# nrf9230_sysctrl register map
Vendor: Nordic Semiconductor; Series: nRF92; File version: 1
Registers are 32-bit, read-write, reset 0x0 unless marked. A register's access mark holds for its fields unless they carry their own. Offsets are from the block's base; [hi:lo] are bit positions; {n}, {i} and the like mark numbered series; 'fields as' and 'values as' point back to an identical list; <NAME> marks a mode.

## PMICC — PMIC Controller
Base 0x5F978000
0x100 EVENTS_FPWMRDYHI — PMIC fPwmRdy went from low to high.
  [0] EVENTS_FPWMRDYHI
    0=NotGenerated (Event not generated); 1=Generated (Event generated)
0x104 EVENTS_FPWMRDYLO — PMIC fPwmRdy went from high to low.
  [0] EVENTS_FPWMRDYLO
    values as EVENTS_FPWMRDYHI.EVENTS_FPWMRDYHI
{0x108+4i} EVENTS_CURRABOVE[{i}] (i=0..8) — Description collection: Current consumption went above the threshold for power rail n. POWER_RAIL_NAME[o] index o <- ((EVENTS_CURRABOVE[n]) MOD (number of power rails))
  [0] EVENTS_CURRABOVE — Current consumption went above the threshold for power rail n. POWER_RAIL_NAME[o] index o <- ((EVENTS_CURRABOVE[n]) MOD (number of power rails))
    values as EVENTS_FPWMRDYHI.EVENTS_FPWMRDYHI
{0x12C+4i} EVENTS_CURRBELOW[{i}] (i=0..8) — Description collection: Current consumption went below the threshold for power rail n. POWER_RAIL_NAME[o] index o <- ((EVENTS_CURRBELOW[n]) MOD (number of power rails))
  [0] EVENTS_CURRBELOW — Current consumption went below the threshold for power rail n. POWER_RAIL_NAME[o] index o <- ((EVENTS_CURRBELOW[n]) MOD (number of power rails))
    values as EVENTS_FPWMRDYHI.EVENTS_FPWMRDYHI
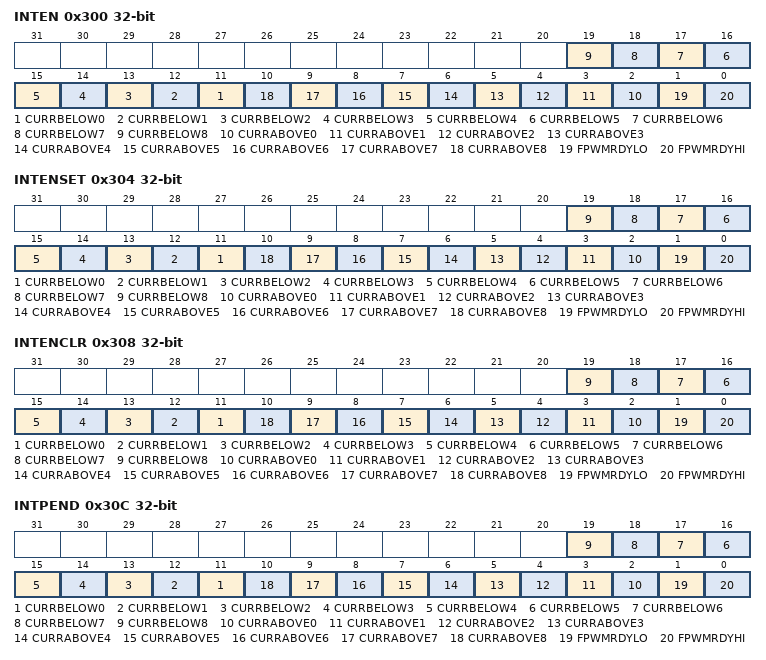
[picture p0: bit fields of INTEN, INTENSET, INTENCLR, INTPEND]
0x300 INTEN — Enable or disable interrupt
  [all] fields
    0=Disabled; 1=Enabled
  [n+11] CURRBELOW{n} (n=0..8) — Enable or disable interrupt for event CURRBELOW[{n}]
  [n+2] CURRABOVE{n} (n=0..8) — Enable or disable interrupt for event CURRABOVE[{n}]
  [1] FPWMRDYLO — Enable or disable interrupt for event FPWMRDYLO
  [0] FPWMRDYHI — Enable or disable interrupt for event FPWMRDYHI
0x304 INTENSET — Enable interrupt
  [all] fields
    on read: 0=Disabled (Read: Disabled); 1=Enabled (Read: Enabled) | on write: 1=Set (Enable)
  [n+11] CURRBELOW{n} (n=0..8) — Write '1' to enable interrupt for event CURRBELOW[{n}]
  [n+2] CURRABOVE{n} (n=0..8) — Write '1' to enable interrupt for event CURRABOVE[{n}]
  [1] FPWMRDYLO — Write '1' to enable interrupt for event FPWMRDYLO
  [0] FPWMRDYHI — Write '1' to enable interrupt for event FPWMRDYHI
0x308 INTENCLR — Disable interrupt
  [all] fields
    on read: 0=Disabled (Read: Disabled); 1=Enabled (Read: Enabled) | on write: 1=Clear (Disable)
  [n+11] CURRBELOW{n} (n=0..8) — Write '1' to disable interrupt for event CURRBELOW[{n}]
  [n+2] CURRABOVE{n} (n=0..8) — Write '1' to disable interrupt for event CURRABOVE[{n}]
  [1] FPWMRDYLO — Write '1' to disable interrupt for event FPWMRDYLO
  [0] FPWMRDYHI — Write '1' to disable interrupt for event FPWMRDYHI
0x30C INTPEND ro — Pending interrupts
  [all] fields
    on read: 0=NotPending (Read: Not pending); 1=Pending (Read: Pending)
  [n+11] CURRBELOW{n} (n=0..8) — Read pending status of interrupt for event CURRBELOW[{n}]
  [n+2] CURRABOVE{n} (n=0..8) — Read pending status of interrupt for event CURRABOVE[{n}]
  [1] FPWMRDYLO — Read pending status of interrupt for event FPWMRDYLO
  [0] FPWMRDYHI — Read pending status of interrupt for event FPWMRDYHI
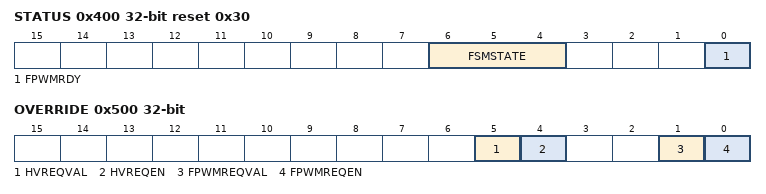
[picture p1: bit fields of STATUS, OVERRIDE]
0x400 STATUS ro reset 0x30 — PMICC Status
  [6:4] FSMSTATE — State machine state
    0=DISABLED (PMICC has been disabled); 1=ULP (ULP or HV_REQ state); 2=PGDREQ (PGD_REQ state); 3=BODHPREQ (BOD_HP_REQ state); 4=HV (HV state); 5=PWMREQ (PWM_REQ state); 6=PWM (PWM state); 7=BODULPREQ (BOD_ULP_REQ state)
  [0] FPWMRDY — State of PMIC fPwmRdy signal
    0=ZERO (fPwmRdy low); 1=ONE (fPwmRdy high)
{0x404+4i} ITHRESHOLD[{i}] (i=0..2) reset 0x32 — Description collection: Current threshold
  [5:0] THRES — Current threshold
0x500 OVERRIDE — Override request outputs
  [5] HVREQVAL — Value to force PMIC HVReq to
  [4] HVREQEN — Whether to force PMIC HVReq
    0=DISABLE (Not forcing HVReq); 1=ENABLE (Forcing HVReq to value in HVREQVAL)
  [1] FPWMREQVAL — Value to force PMIC fPwmReq to
  [0] FPWMREQEN — Whether to force PMIC fPwmReq
    0=DISABLE (Not forcing fPwmReq); 1=ENABLE (Forcing fPwmReq to value in FPWMREQVAL)
